VERSION ""

NS_ :

BS_:

BU_: VEHICLE

BO_ 544 BRAKE_PRESSURE: 8 VEHICLE
 SG_ BRAKE_PRESSURE : 24|12@1+ (0.025,0) [0|0] "bar" VEHICLE

BO_ 688 STEERING_ANGLE: 8 VEHICLE
 SG_ STEERING_WHEEL_ANGLE : 0|16@1- (0.1,0) [0|0] "degrees" VEHICLE

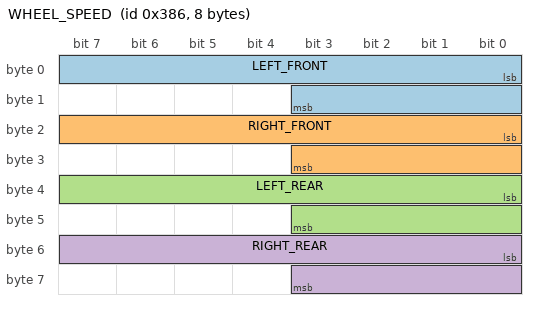
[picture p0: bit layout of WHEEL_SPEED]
BO_ 902 WHEEL_SPEED: 8 VEHICLE
 SG_ LEFT_FRONT : 0|12@1+ (0.03125,0) [0|0] "kph" VEHICLE
 SG_ RIGHT_FRONT : 16|12@1+ (0.03125,0) [0|0] "kph" VEHICLE
 SG_ LEFT_REAR : 32|12@1+ (0.03125,0) [0|0] "kph" VEHICLE
 SG_ RIGHT_REAR : 48|12@1+ (0.03125,0) [0|0] "kph" VEHICLE

CM_ BO_ 544 "Vehicle Brake Pressure";
CM_ BO_ 688 "Vehicle Steering Angle";
CM_ BO_ 902 "Vehicle Individual Wheel Speed";
